AUTOSAR XML (schema 4-3-0)
standard types defined: boolean, float32, sint16, uint16, uint8, sint16_DataConstr, uint16_DataConstr, boolean_DataConstr
package /ComponentTypes/AspSWC/ConstantSpecifications
  4 x constant specification:
    SteerWhlTrqAddl_CS: value-spec=SteerWhlTrqAddl_Default:0
    SteerWhlTrqCtrlActive_CS: value-spec=SteerWhlTrqCtrlActive_Default:0
    SteerWhlTrqCtrlLimActvd_CS: value-spec=SteerWhlTrqCtrlLimActvd_Default:0
    SteerWhlTrqCtrlRatio_CS: value-spec=SteerWhlTrqCtrlRatio_Default:0
package /ComponentTypes/AspSWC/DataTypes/ImplementationDataTypes
  impl type SteerWhlTqLim_STC: compu {0=NoLim, 1=MagLimActvd, 2=RateLimActvd, 3=MagRateLimActvd, else NoLim}, implementation-data-type=uint8, type-emitter=RTE
package /ComponentTypes/AspSWC/PortInterfaces
  4 x sender receiver interface:
    SteerWhlTrqAddl_Asp_IF: invalidation-policy{data-element=SteerWhlTrqAddl, handle-invalid=DONT-INVALIDATE}
      data SteerWhlTrqAddl: base-type=float32, range raw >-INF..<INF, type=float32, init-value=constant-reference=SteerWhlTrqAddl_CS
    SteerWhlTrqCtrlActive_Asp_IF: invalidation-policy{data-element=SteerWhlTrqCtrlActive, handle-invalid=DONT-INVALIDATE}
      data SteerWhlTrqCtrlActive: type=boolean, init-value=constant-reference=SteerWhlTrqCtrlActive_CS
    SteerWhlTrqCtrlLimActvd_Asp_IF: invalidation-policy{data-element=SteerWhlTrqCtrlLimActvd, handle-invalid=DONT-INVALIDATE}
      data SteerWhlTrqCtrlLimActvd: type=SteerWhlTqLim_STC, init-value=constant-reference=SteerWhlTrqCtrlLimActvd_CS
    SteerWhlTrqCtrlRatio_Asp_IF: invalidation-policy{data-element=SteerWhlTrqCtrlRatio, handle-invalid=DONT-INVALIDATE}
      data SteerWhlTrqCtrlRatio: type=float32, init-value=constant-reference=SteerWhlTrqCtrlRatio_CS
package /ComponentTypes/StcSWC
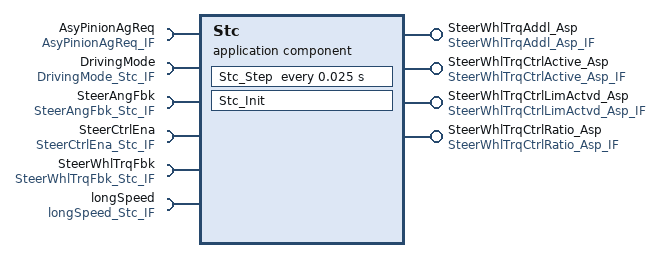
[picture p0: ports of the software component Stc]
  application sw component type Stc
    4 x require port:
      AsyPinionAgReq: nonqueued-receiver-com-spec{data-element=AsyPinionAgReq, init-value=constant-reference=AsyPinionAgReq_CS}, required-interface=AsyPinionAgReq_IF
      DrivingMode: nonqueued-receiver-com-spec{data-element=DrivingMode, init-value=constant-reference=DrivingMode_CS}, required-interface=DrivingMode_Stc_IF
      SteerAngFbk: nonqueued-receiver-com-spec{data-element=SteerAngFbk, init-value=constant-reference=SteerAngFbk_CS}, required-interface=SteerAngFbk_Stc_IF
      SteerCtrlEna: nonqueued-receiver-com-spec{data-element=SteerCtrlEna, init-value=constant-reference=SteerCtrlEna_CS}, required-interface=SteerCtrlEna_Stc_IF
    4 x provide port:
      SteerWhlTrqAddl_Asp: nonqueued-sender-com-spec{data-element=SteerWhlTrqAddl, transmission-acknowledge=timeout=0.0, uses-end-to-end-protection=0, init-value=constant-reference=SteerWhlTrqAddl_CS}, provided-interface=SteerWhlTrqAddl_Asp_IF
      SteerWhlTrqCtrlActive_Asp: nonqueued-sender-com-spec{data-element=SteerWhlTrqCtrlActive, transmission-acknowledge=timeout=0.0, uses-end-to-end-protection=0, init-value=constant-reference=SteerWhlTrqCtrlActive_CS}, provided-interface=SteerWhlTrqCtrlActive_Asp_IF
      SteerWhlTrqCtrlLimActvd_Asp: nonqueued-sender-com-spec{data-element=SteerWhlTrqCtrlLimActvd, transmission-acknowledge=timeout=0.0, uses-end-to-end-protection=0, init-value=constant-reference=SteerWhlTrqCtrlLimActvd_CS}, provided-interface=SteerWhlTrqCtrlLimActvd_Asp_IF
      SteerWhlTrqCtrlRatio_Asp: nonqueued-sender-com-spec{data-element=SteerWhlTrqCtrlRatio, transmission-acknowledge=timeout=0.0, uses-end-to-end-protection=0, init-value=constant-reference=SteerWhlTrqCtrlRatio_CS}, provided-interface=SteerWhlTrqCtrlRatio_Asp_IF
    require port SteerWhlTrqFbk: nonqueued-receiver-com-spec{data-element=SteerWhlTrqFbk, init-value=constant-reference=SteerWhlTrqFbk_CS}, required-interface=SteerWhlTrqFbk_Stc_IF
    require port longSpeed: nonqueued-receiver-com-spec{data-element=longSpeed, init-value=constant-reference=longSpeed_CS}, required-interface=longSpeed_Stc_IF
    behavior Stc_IB_1
      init event Stc_Init_IE: start-on-event=Stc_Init
      timing event Stc_Step_TE: start-on-event=Stc_Step, period=0.025
      runnable Stc_Init
        data-receive-point-by-arguments:
          6 x access:
            REC_AsyPinionAgReq_IF_DE: accessed-variable=AsyPinionAgReq.AsyPinionAgReq
            REC_DrivingMode_IF_DE: accessed-variable=DrivingMode.DrivingMode
            REC_SteerAngFbk_IF_DE: accessed-variable=SteerAngFbk.SteerAngFbk
            REC_SteerCtrlEna_IF_DE: accessed-variable=SteerCtrlEna.SteerCtrlEna
            REC_SteerWhlTrqFbk_IF_DE: accessed-variable=SteerWhlTrqFbk.SteerWhlTrqFbk
            REC_longSpeed_IF_DE: accessed-variable=longSpeed.longSpeed
        data-send-points:
          4 x access:
            SEND_SteerWhlTqAddl_DE: accessed-variable=SteerWhlTrqAddl_Asp.SteerWhlTrqAddl
            SEND_SteerWhlTrqCtrlActive_DE: accessed-variable=SteerWhlTrqCtrlActive_Asp.SteerWhlTrqCtrlActive
            SEND_SteerWhlTrqCtrlLimActvd_DE: accessed-variable=SteerWhlTrqCtrlLimActvd_Asp.SteerWhlTrqCtrlLimActvd
            SEND_SteerWhlTrqCtrlRatio_DE: accessed-variable=SteerWhlTrqCtrlRatio_Asp.SteerWhlTrqCtrlRatio
      runnable Stc_Step
        data-receive-point-by-arguments:
          5 x access:
            drparg_DE: accessed-variable=AsyPinionAgReq.AsyPinionAgReq
            drparg_DE1: accessed-variable=SteerAngFbk.SteerAngFbk
            drparg_DE2: accessed-variable=SteerWhlTrqFbk.SteerWhlTrqFbk
            drparg_DE3: accessed-variable=longSpeed.longSpeed
            drparg_DE4: accessed-variable=SteerCtrlEna.SteerCtrlEna
        data-receive-point-by-values:
          access drparg_DE5: accessed-variable=DrivingMode.DrivingMode
        data-send-points:
          4 x access:
            dsp_DE: accessed-variable=SteerWhlTrqAddl_Asp.SteerWhlTrqAddl
            dsp_DE1: accessed-variable=SteerWhlTrqCtrlActive_Asp.SteerWhlTrqCtrlActive
            dsp_DE2: accessed-variable=SteerWhlTrqCtrlLimActvd_Asp.SteerWhlTrqCtrlLimActvd
            dsp_DE3: accessed-variable=SteerWhlTrqCtrlRatio_Asp.SteerWhlTrqCtrlRatio
  swc implementation Stc_Implementation: sw-version=1.0.1, behavior=Stc_IB_1
    code-descriptors:
      code Default: artifact-descriptors=autosar-engineering-object={short-label=Default, category=SWSRC}
package /ComponentTypes/StcSWC/ConstantSpecifications
  7 x constant specification:
    AsyPinionAgReq_CS: value-spec=AsyPinionAgReq_Default:0
    DrivingMode_CS: value-spec=DrivingMode_Default:1
    SteerAngFbk_CS: value-spec=SteerWhlAngFbk_Default:0
    SteerCtrlEna_CS: value-spec=SteerCtrlEna_Default:0
    SteerWhlTrqFbk_CS: value-spec=SteerWhlTrqFbk_Default:0
    VehTyp_CS: value-spec=VehTyp_Default:1
    longSpeed_CS: value-spec=longSpeed_Default:0
package /ComponentTypes/StcSWC/DataTypes/ImplementationDataTypes
  impl type DrivingMode_STC: compu {0=Resvd0, 1=Standard, 2=Comfort, 3=Sport, else Standard}, implementation-data-type=uint8, type-emitter=RTE
package /ComponentTypes/StcSWC/PortInterfaces
  6 x sender receiver interface:
    AsyPinionAgReq_IF: invalidation-policy{data-element=AsyPinionAgReq, handle-invalid=DONT-INVALIDATE}
      data AsyPinionAgReq: type=float32, init-value=constant-reference=AsyPinionAgReq_CS
    DrivingMode_Stc_IF: invalidation-policy{data-element=DrivingMode, handle-invalid=DONT-INVALIDATE}
      data DrivingMode: type=DrivingMode_STC, init-value=constant-reference=DrivingMode_CS
    SteerAngFbk_Stc_IF: invalidation-policy{data-element=SteerAngFbk, handle-invalid=DONT-INVALIDATE}
      data SteerAngFbk: type=float32, init-value=constant-reference=SteerAngFbk_CS
    SteerCtrlEna_Stc_IF: invalidation-policy{data-element=SteerCtrlEna, handle-invalid=DONT-INVALIDATE}
      data SteerCtrlEna: type=uint8, init-value=constant-reference=SteerCtrlEna_CS
    SteerWhlTrqFbk_Stc_IF: invalidation-policy{data-element=SteerWhlTrqFbk, handle-invalid=DONT-INVALIDATE}
      data SteerWhlTrqFbk: type=float32, init-value=constant-reference=SteerWhlTrqFbk_CS
    longSpeed_Stc_IF: invalidation-policy{data-element=longSpeed, handle-invalid=DONT-INVALIDATE}
      data longSpeed: type=float32, init-value=constant-reference=longSpeed_CS
